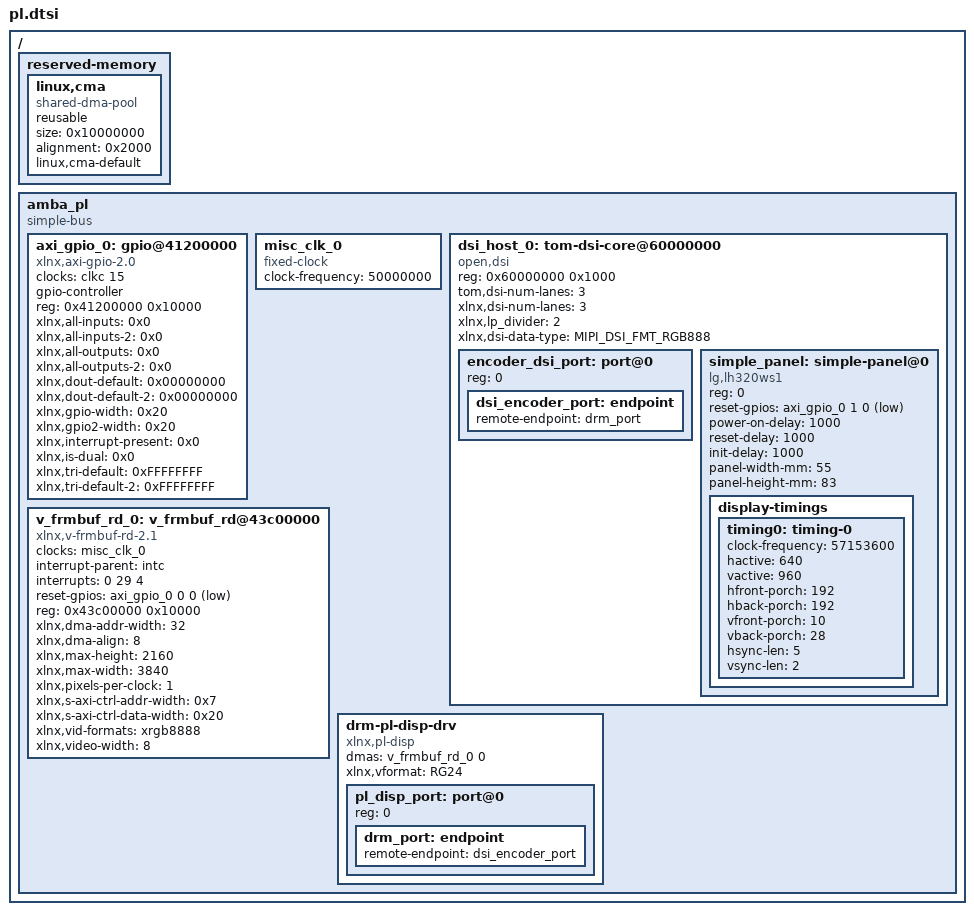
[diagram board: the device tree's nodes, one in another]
/*
 * CAUTION: This file is automatically generated by Xilinx.
 * Version: HSI 2018.3.1
 * Today is: Sun May 12 16:37:27 2019
 */

//#include <dt-bindings/drm/mipi-dsi.h>
#define MIPI_DSI_FMT_RGB888		0
#define MIPI_DSI_FMT_RGB666		1
#define MIPI_DSI_FMT_RGB666_PACKED	2
#define MIPI_DSI_FMT_RGB565		3


/ {
    
    
    

    reserved-memory {
		#address-cells = <1>;
		#size-cells = <1>;
		ranges;

		/* global autoconfigured region for contiguous allocations */
		linux,cma {
			compatible = "shared-dma-pool";
			reusable;
			size = <0x10000000>;
			alignment = <0x2000>;
			linux,cma-default;
		};
    };

    
	amba_pl: amba_pl {
		#address-cells = <1>;
		#size-cells = <1>;
		compatible = "simple-bus";
		ranges ;
		axi_gpio_0: gpio@41200000 {
			#gpio-cells = <3>;
			clock-names = "s_axi_aclk";
			clocks = <&clkc 15>;
			compatible = "xlnx,axi-gpio-2.0", "xlnx,xps-gpio-1.00.a";
			gpio-controller ;
			reg = <0x41200000 0x10000>;
			xlnx,all-inputs = <0x0>;
			xlnx,all-inputs-2 = <0x0>;
			xlnx,all-outputs = <0x0>;
			xlnx,all-outputs-2 = <0x0>;
			xlnx,dout-default = <0x00000000>;
			xlnx,dout-default-2 = <0x00000000>;
			xlnx,gpio-width = <0x20>;
			xlnx,gpio2-width = <0x20>;
			xlnx,interrupt-present = <0x0>;
			xlnx,is-dual = <0x0>;
			xlnx,tri-default = <0xFFFFFFFF>;
			xlnx,tri-default-2 = <0xFFFFFFFF>;
		};
		misc_clk_0: misc_clk_0 {
			#clock-cells = <0>;
			clock-frequency = <50000000>;
			compatible = "fixed-clock";
		};

		dsi_host_0: tom-dsi-core@60000000 {
			compatible = "open,dsi";
			reg = <0x60000000 0x1000>;
			tom,dsi-num-lanes = <3>;
            xlnx,dsi-num-lanes = <3>;
            
            xlnx,lp_divider=<2>;
            
            xlnx,dsi-data-type = <MIPI_DSI_FMT_RGB888>;
			#address-cells = <1>;
			#size-cells = <1>;

/*			tom,dsi-data-type = <MIPI_DSI_FMT_RGB888>;
			#xlnx,vpss = <&v_proc_ss_0>;
			#clock-names = "dphy_clk_200M", "s_axis_aclk";
			#clocks = <&misc_clk_0>, <&misc_clk_1>;*/

			encoder_dsi_port: port@0
			{
				reg = <0>;
				dsi_encoder_port: endpoint {
					remote-endpoint = <&drm_port>;
				};
			};

			/*simple_panel: simple-panel@0 {
				compatible = "tom,opendso_panel";
				reg = <0>;
			};*/

			/*simple_panel: simple-panel@0
			{
				compatible = "auo,b101uan01";
				//compatible = "panel-samsung-s6e8aa0";
                
				reg = <0>;
			};*/
            
            
            simple_panel: simple-panel@0 {
                compatible = "lg,lh320ws1";
                reg = <0>;
                reset-gpios =  <&axi_gpio_0 1 0 1>;
                
                power-on-delay=<1000>;
                reset-delay=<1000>;
                init-delay=<1000>;
                panel-width-mm=<55>;
                panel-height-mm=<83>;
                
                
                display-timings {
                    timing0: timing-0 {
                        clock-frequency = <57153600>;
                        hactive = <640>;
                        vactive = <960>;
                        hfront-porch = <192>;
                        hback-porch = <192>;
                        vfront-porch = <10>;
                        vback-porch = <28>;
                        
                        //TODO: sprawdzic do czego to
                        hsync-len = <5>;
                        vsync-len = <2>;
                    };
                };
    
    
    
                //power-supply = <&reg_display>;
                //reset-gpios = <&r_pio 0 5 GPIO_ACTIVE_LOW>; 
               // backlight = <&pwm_bl>;
            };
            
            
           /* simple_panel: simple-panel@0 {
                compatible = "bananapi,lhr050h41", "ilitek,ili9881c";
                reg = <0>;
                reset-gpios =  <&axi_gpio_0 1 0 1>;
                //power-supply = <&reg_display>;
                //reset-gpios = <&r_pio 0 5 GPIO_ACTIVE_LOW>; 
               // backlight = <&pwm_bl>;
            };*/
        };

		/*drm-pl-disp-drv {
			compatible = "xlnx,pl-disp";
			dmas = <&v_frmbuf_rd_0 0>;
			dma-names = "dma0";
			xlnx,vformat = "RGB888";
			// xlnx,bridge = <&dsi_host_0>; 

			pl_disp_output: port@0
			{
				reg = <0>;
				dmaengine_mipi: endpoint {
					remote-endpoint = <&dsi_encoder_port>;
				};
			};
		};*/



		v_frmbuf_rd_0: v_frmbuf_rd@43c00000 {
			#dma-cells = <1>;
			clock-names = "ap_clk";
			clocks = <&misc_clk_0>;
			compatible = "xlnx,v-frmbuf-rd-2.1", "xlnx,axi-frmbuf-rd-v2.1";
			interrupt-names = "interrupt";
			interrupt-parent = <&intc>;
			interrupts = <0 29 4>;
			reset-gpios = <&axi_gpio_0 0 0 1>;
			reg = <0x43c00000 0x10000>;
			xlnx,dma-addr-width = <32>;
			xlnx,dma-align = <8>;
			xlnx,max-height = <2160>;
			xlnx,max-width = <3840>;
			xlnx,pixels-per-clock = <1>;
			xlnx,s-axi-ctrl-addr-width = <0x7>;
			xlnx,s-axi-ctrl-data-width = <0x20>;
			xlnx,vid-formats = "xrgb8888";
			xlnx,video-width = <8>;
		};

        drm-pl-disp-drv {
            compatible = "xlnx,pl-disp";
            dmas = <&v_frmbuf_rd_0 0>;
            dma-names = "dma0";
            xlnx,vformat = "RG24";
            //xlnx,bridge = <&v_tc_0>;
            pl_disp_port: port@0 {
                reg = <0>;
                drm_port: endpoint {
                    remote-endpoint = <&dsi_encoder_port>;
                };
            };
        };
       
        /*xilinx_drm: xilinx_drm {
            compatible = "xlnx,drm";
            ports {
                #address-cells = <1>;
                #size-cells = <0>;
                port@0 {
                    reg = <0>;
                    drm_port: endpoint {
                        remote-endpoint = <&dsi_encoder_port>;
                    };
                };
            };
            planes {
                xlnx,pixel-format = "rgb888";
                plane0 {
                    dmas = <&v_frmbuf_rd_0 0>;
                    dma-names = "v_frmbuf_rd_0";
                };
            };
        };*/
    


	};
};

